# STM32H750 register map
File version: 2.7
CPU: CM7 r0p1, little endian, MPU, FPU, 4 interrupt priority bits
Registers are 32-bit, read-write, reset 0x0 unless marked. A register's access mark holds for its fields unless they carry their own. Offsets are from the block's base; [hi:lo] are bit positions; {n}, {i} and the like mark numbered series.

## RAMECC1 — ECC controller is associated to each RAM area
Base 0x52009000
Same registers: RAMECC2 0x48023000
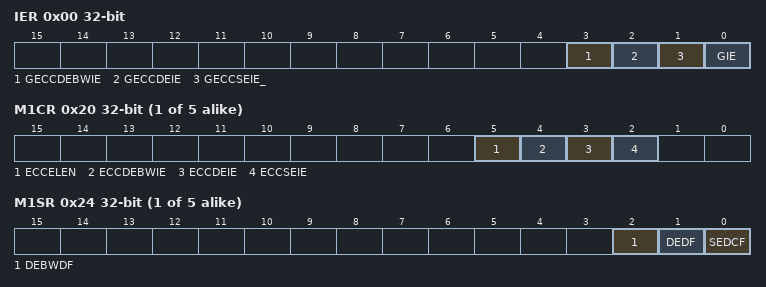
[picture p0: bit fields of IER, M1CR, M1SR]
0x00 IER — RAMECC interrupt enable register
  [3] GECCDEBWIE — Global ECC double error on byte write (BW) interrupt enable
  [2] GECCDEIE — Global ECC double error interrupt enable
  [1] GECCSEIE_ — Global ECC single error interrupt enable
  [0] GIE — Global interrupt enable
{0x0+0x20*i} M{i}CR (i=1..5) — RAMECC monitor x configuration register
  [5] ECCELEN — ECC error latching enable
  [4] ECCDEBWIE — ECC double error on byte write (BW) interrupt enable
  [3] ECCDEIE — ECC double error interrupt enable
  [2] ECCSEIE — ECC single error interrupt enable
{0x4+0x20*i} M{i}SR (i=1..5) — RAMECC monitor x status register
  [2] DEBWDF — ECC double error on byte write (BW) detected flag
  [1] DEDF — ECC double error detected flag
  [0] SEDCF — ECC single error detected and corrected flag
{0x8+0x20*i} M{i}FAR ro (i=1..4) — RAMECC monitor x failing address register
  [31:0] FADD — ECC error failing address
{0xC+0x20*i} M{i}FDRL ro (i=1..5) — RAMECC monitor x failing data low register
  [31:0] FDATAL — Failing data low
0x30 M1FDRH ro — RAMECC monitor x failing data high register
  [31:0] FDATAH — Failing data high (64-bit memory)
0x34 M1FECR — RAMECC monitor x failing ECC error code register
  [31:0] FEC — Failing error code
0x50 M2FDRH — RAMECC monitor x failing data high register
  [31:0] FDATAH — Failing data high (64-bit memory)
0x58 M2FECR — RAMECC monitor x failing ECC error code register
  [31:0] FEC — Failing error code
0x70 M3FDRH ro — RAMECC monitor x failing data high register
  [31:0] FDATAH — Failing data high (64-bit memory)
0x7C M3FECR ro — RAMECC monitor x failing ECC error code register
  [31:0] FEC — Failing error code
0x90 M4FDRH ro — RAMECC monitor x failing data high register
  [31:0] FDATAH — Failing data high (64-bit memory)
0x90 M4FECR ro (alternate view of M4FDRH) — RAMECC monitor x failing ECC error code register
  [31:0] FEC — Failing error code
0xA8 M5FAR — RAMECC monitor x failing address register
  [31:0] FADD — ECC error failing address
0xB0 M5FDRH ro — RAMECC monitor x failing data high register
  [31:0] FEC — Failing error code
0xB4 M5FECR ro — RAMECC monitor x failing ECC error code register
  [31:0] FEC — Failing error code

## RAMECC3 — ECC controller is associated to each RAM area
Base 0x58027000
Registers as RAMECC1, without M{n}CR (n=3..5), M{n}SR (n=3..5), M{n}FAR (n=3..5), M{n}FDRL (n=3..5), M{n}FDRH (n=3..5), M{n}FECR (n=3..5).

## ADC3_Common — Analog-to-Digital Converter
Base 0x58026300
Same registers: ADC12_Common 0x40022300
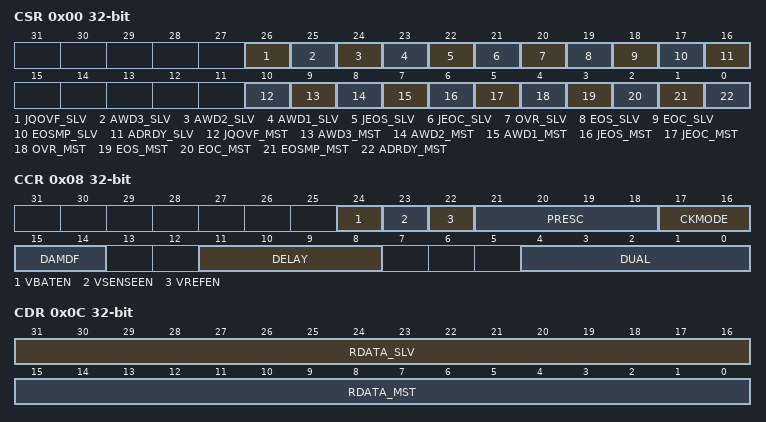
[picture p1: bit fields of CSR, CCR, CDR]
0x00 CSR ro — ADC Common status register
  [26] JQOVF_SLV — Injected Context Queue Overflow flag of the slave ADC
  [25] AWD3_SLV — Analog watchdog 3 flag of the slave ADC
  [24] AWD2_SLV — Analog watchdog 2 flag of the slave ADC
  [23] AWD1_SLV — Analog watchdog 1 flag of the slave ADC
  [22] JEOS_SLV — End of injected sequence flag of the slave ADC
  [21] JEOC_SLV — End of injected conversion flag of the slave ADC
  [20] OVR_SLV — Overrun flag of the slave ADC
  [19] EOS_SLV — End of regular sequence flag of the slave ADC
  [18] EOC_SLV — End of regular conversion of the slave ADC
  [17] EOSMP_SLV — End of Sampling phase flag of the slave ADC
  [16] ADRDY_SLV — Slave ADC ready
  [10] JQOVF_MST — Injected Context Queue Overflow flag of the master ADC
  [9] AWD3_MST — Analog watchdog 3 flag of the master ADC
  [8] AWD2_MST — Analog watchdog 2 flag of the master ADC
  [7] AWD1_MST — Analog watchdog 1 flag of the master ADC
  [6] JEOS_MST — End of injected sequence flag of the master ADC
  [5] JEOC_MST — End of injected conversion flag of the master ADC
  [4] OVR_MST — Overrun flag of the master ADC
  [3] EOS_MST — End of regular sequence flag of the master ADC
  [2] EOC_MST — End of regular conversion of the master ADC
  [1] EOSMP_MST — End of Sampling phase flag of the master ADC
  [0] ADRDY_MST — Master ADC ready
0x08 CCR — ADC common control register
  [24] VBATEN — VBAT enable
  [23] VSENSEEN — Temperature sensor enable
  [22] VREFEN — VREFINT enable
  [21:18] PRESC — ADC prescaler
  [17:16] CKMODE — ADC clock mode
  [15:14] DAMDF — Dual ADC Mode Data Format
  [11:8] DELAY — Delay between 2 sampling phases
  [4:0] DUAL — Dual ADC mode selection
0x0C CDR ro — ADC common regular data register for dual and triple modes
  [31:16] RDATA_SLV — Regular data of the slave ADC
  [15:0] RDATA_MST — Regular data of the master ADC
